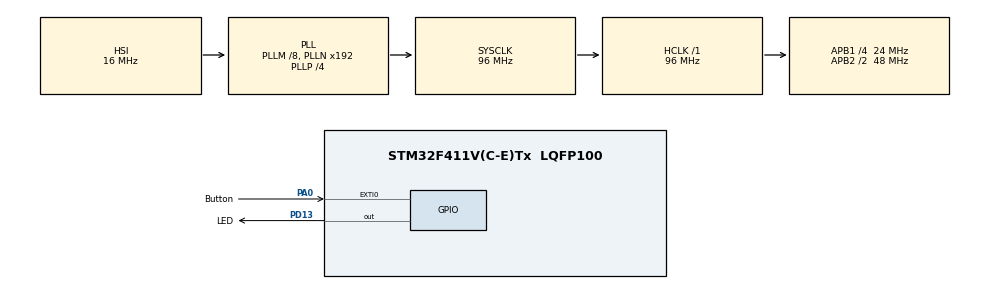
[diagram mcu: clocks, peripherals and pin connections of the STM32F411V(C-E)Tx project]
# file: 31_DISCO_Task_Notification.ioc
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FREERTOS.Tasks01=defaultTask,24,128,StartDefaultTask,Default,NULL,Dynamic,NULL,NULL
FREERTOS.configUSE_NEWLIB_REENTRANT=1
Mcu.Family=STM32F4
Mcu.Name=STM32F411V(C-E)Tx
Mcu.Package=LQFP100
NVIC.EXTI0_IRQn=true\:5\:0\:false\:false\:true\:true\:true\:true\:true
NVIC.PriorityGroup=NVIC_PRIORITYGROUP_4
PA0-WKUP.GPIO_Label=Button
PA0-WKUP.GPIO_ModeDefaultEXTI=GPIO_MODE_IT_FALLING
PA0-WKUP.Signal=GPXTI0
PA13.GPIO_Label=SWDIO
PA13.Mode=Serial_Wire
PA13.Signal=SYS_JTMS-SWDIO
PA14.GPIO_Label=SWCLK
PA14.Mode=Serial_Wire
PA14.Signal=SYS_JTCK-SWCLK
PB3.GPIO_Label=SWO
PB3.Signal=SYS_JTDO-SWO
PD13.GPIO_Label=LED
PD13.Signal=GPIO_Output
PH0\ -\ OSC_IN.Mode=HSE-External-Clock-Source
PH0\ -\ OSC_IN.Signal=RCC_OSC_IN
PH1\ -\ OSC_OUT.Mode=HSE-External-Clock-Source
PH1\ -\ OSC_OUT.Signal=RCC_OSC_OUT
ProjectManager.HeapSize=0x200
ProjectManager.StackSize=0x400
ProjectManager.TargetToolchain=STM32CubeIDE
RCC.48MHZClocksFreq_Value=48000000
RCC.AHBFreq_Value=96000000
RCC.APB1CLKDivider=RCC_HCLK_DIV4
RCC.APB1Freq_Value=24000000
RCC.APB1TimFreq_Value=48000000
RCC.APB2CLKDivider=RCC_HCLK_DIV2
RCC.APB2Freq_Value=48000000
RCC.APB2TimFreq_Value=96000000
RCC.CortexFreq_Value=96000000
RCC.HCLKFreq_Value=96000000
RCC.HSE_VALUE=8000000
RCC.HSI_VALUE=16000000
RCC.LSE_VALUE=32768
RCC.PLLI2SM=5
RCC.PLLI2SN=200
RCC.PLLM=8
RCC.PLLP=RCC_PLLP_DIV4
RCC.PLLQ=8
RCC.SYSCLKFreq_VALUE=96000000
RCC.SYSCLKSource=RCC_SYSCLKSOURCE_PLLCLK
RCC.VCOOutputFreq_Value=384000000
VP_FREERTOS_VS_CMSIS_V2.Mode=CMSIS_V2
board=STM32F411E-DISCO

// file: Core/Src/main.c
/* USER CODE BEGIN Header */
/**
  ******************************************************************************
  * @file           : main.c
  * @brief          : Main program body
  ******************************************************************************
  * @attention
  *
  * Copyright (c) 2023 STMicroelectronics.
  * All rights reserved.
  *
  * This software is licensed under terms that can be found in the LICENSE file
  * in the root directory of this software component.
  * If no LICENSE file comes with this software, it is provided AS-IS.
  *
  ******************************************************************************
  */
/* USER CODE END Header */
#include "main.h"
#include "cmsis_os.h"

/* USER CODE BEGIN Includes */
#include "stdio.h"
#include "stdbool.h"
/* USER CODE END Includes */

/* USER CODE BEGIN PM */
#define STACK_SIZE 128
/* USER CODE END PM */

/* Definitions for defaultTask */
//osThreadId_t defaultTaskHandle;
//const osThreadAttr_t defaultTask_attributes = {
//  .name = "defaultTask",
//  .stack_size = 128 * 4,
//  .priority = (osPriority_t) osPriorityNormal,
//};
/* USER CODE BEGIN PV */
bool button_pressed = false;
static TaskHandle_t xHandlerTask = NULL;
/* USER CODE END PV */

void SystemClock_Config(void);
static void MX_GPIO_Init(void);
//void StartDefaultTask(void *argument);

/* USER CODE BEGIN PFP */
void HandlerTask (void *pvParameters);
/* USER CODE END PFP */

int main(void)
{

  /* MCU Configuration--------------------------------------------------------*/

  /* Reset of all peripherals, Initializes the Flash interface and the Systick. */
  HAL_Init();

  /* Configure the system clock */
  SystemClock_Config();

  /* Initialize all configured peripherals */
  MX_GPIO_Init();
  /* USER CODE BEGIN 2 */
  xTaskCreate(HandlerTask,
  		  	  "HandlerTask",
  			  STACK_SIZE,
  			  NULL,
  			  3,
  			  &xHandlerTask);

  vTaskStartScheduler();
  /* USER CODE END 2 */

  /* Init scheduler */
//  osKernelInitialize();

  /* Create the thread(s) */
  /* creation of defaultTask */
//  defaultTaskHandle = osThreadNew(StartDefaultTask, NULL, &defaultTask_attributes);

  /* Start scheduler */
//  osKernelStart();

  /* We should never get here as control is now taken by the scheduler */
  /* Infinite loop */
  while (1)
  {

  }
}

void SystemClock_Config(void)
{
  RCC_OscInitTypeDef RCC_OscInitStruct = {0};
  RCC_ClkInitTypeDef RCC_ClkInitStruct = {0};

  /** Configure the main internal regulator output voltage
  */
  __HAL_RCC_PWR_CLK_ENABLE();
  __HAL_PWR_VOLTAGESCALING_CONFIG(PWR_REGULATOR_VOLTAGE_SCALE1);

  /** Initializes the RCC Oscillators according to the specified parameters
  * in the RCC_OscInitTypeDef structure.
  */
  RCC_OscInitStruct.OscillatorType = RCC_OSCILLATORTYPE_HSI;
  RCC_OscInitStruct.HSIState = RCC_HSI_ON;
  RCC_OscInitStruct.HSICalibrationValue = RCC_HSICALIBRATION_DEFAULT;
  RCC_OscInitStruct.PLL.PLLState = RCC_PLL_ON;
  RCC_OscInitStruct.PLL.PLLSource = RCC_PLLSOURCE_HSI;
  RCC_OscInitStruct.PLL.PLLM = 8;
  RCC_OscInitStruct.PLL.PLLN = 192;
  RCC_OscInitStruct.PLL.PLLP = RCC_PLLP_DIV4;
  RCC_OscInitStruct.PLL.PLLQ = 8;
  if (HAL_RCC_OscConfig(&RCC_OscInitStruct) != HAL_OK)
  {
    Error_Handler();
  }

  /** Initializes the CPU, AHB and APB buses clocks
  */
  RCC_ClkInitStruct.ClockType = RCC_CLOCKTYPE_HCLK|RCC_CLOCKTYPE_SYSCLK
                              |RCC_CLOCKTYPE_PCLK1|RCC_CLOCKTYPE_PCLK2;
  RCC_ClkInitStruct.SYSCLKSource = RCC_SYSCLKSOURCE_PLLCLK;
  RCC_ClkInitStruct.AHBCLKDivider = RCC_SYSCLK_DIV1;
  RCC_ClkInitStruct.APB1CLKDivider = RCC_HCLK_DIV4;
  RCC_ClkInitStruct.APB2CLKDivider = RCC_HCLK_DIV2;

  if (HAL_RCC_ClockConfig(&RCC_ClkInitStruct, FLASH_LATENCY_3) != HAL_OK)
  {
    Error_Handler();
  }
}

static void MX_GPIO_Init(void)
{
  GPIO_InitTypeDef GPIO_InitStruct = {0};

  /* GPIO Ports Clock Enable */
  __HAL_RCC_GPIOH_CLK_ENABLE();
  __HAL_RCC_GPIOA_CLK_ENABLE();
  __HAL_RCC_GPIOD_CLK_ENABLE();
  __HAL_RCC_GPIOB_CLK_ENABLE();

  /*Configure GPIO pin Output Level */
  HAL_GPIO_WritePin(LED_GPIO_Port, LED_Pin, GPIO_PIN_RESET);

  /*Configure GPIO pin : Button_Pin */
  GPIO_InitStruct.Pin = Button_Pin;
  GPIO_InitStruct.Mode = GPIO_MODE_IT_FALLING;
  GPIO_InitStruct.Pull = GPIO_NOPULL;
  HAL_GPIO_Init(Button_GPIO_Port, &GPIO_InitStruct);

  /*Configure GPIO pin : LED_Pin */
  GPIO_InitStruct.Pin = LED_Pin;
  GPIO_InitStruct.Mode = GPIO_MODE_OUTPUT_PP;
  GPIO_InitStruct.Pull = GPIO_NOPULL;
  GPIO_InitStruct.Speed = GPIO_SPEED_FREQ_LOW;
  HAL_GPIO_Init(LED_GPIO_Port, &GPIO_InitStruct);

  /* EXTI interrupt init*/
  HAL_NVIC_SetPriority(EXTI0_IRQn, 5, 0);
  HAL_NVIC_EnableIRQ(EXTI0_IRQn);

}

/* USER CODE BEGIN 4 */
void HandlerTask (void *pvParameters)
{
	const TickType_t xMaxExpectedBlockTime = pdMS_TO_TICKS(100);
	uint32_t time;
	uint32_t variable_jump;
	while(1)
	{
//		if (0 != ulTaskNotifyTake(pdTRUE, xMaxExpectedBlockTime))		// like a binary semaphore
		if (0 != ulTaskNotifyTake(pdFALSE, xMaxExpectedBlockTime))		// like a counting semaphore
		{
			// Do something
			  for (time = 1000; time > 0; time = time - variable_jump)
			  {
				  HAL_GPIO_TogglePin(LED_GPIO_Port, LED_Pin);
				  HAL_Delay(time);
				  if (time > 250)
				  {
					  variable_jump = 50;
				  }
				  else
				  {
					  variable_jump = 10;
				  }
			  }
			  HAL_GPIO_WritePin(LED_GPIO_Port, LED_Pin, GPIO_PIN_RESET);
		}
		else
		{
			// Do something
		}
	}
}

void HAL_GPIO_EXTI_Callback(uint16_t GPIO_Pin)
{
	BaseType_t xHighPriorityTaskWoken = pdFALSE;

	vTaskNotifyGiveFromISR(xHandlerTask, &xHighPriorityTaskWoken);

	portYIELD_FROM_ISR(xHighPriorityTaskWoken);		// request a context switch
}
/* USER CODE END 4 */

void StartDefaultTask(void *argument)
{
  for(;;)
  {
    osDelay(1);
  }
}

void Error_Handler(void)
{
  __disable_irq();
  while (1)
  {
  }
}
